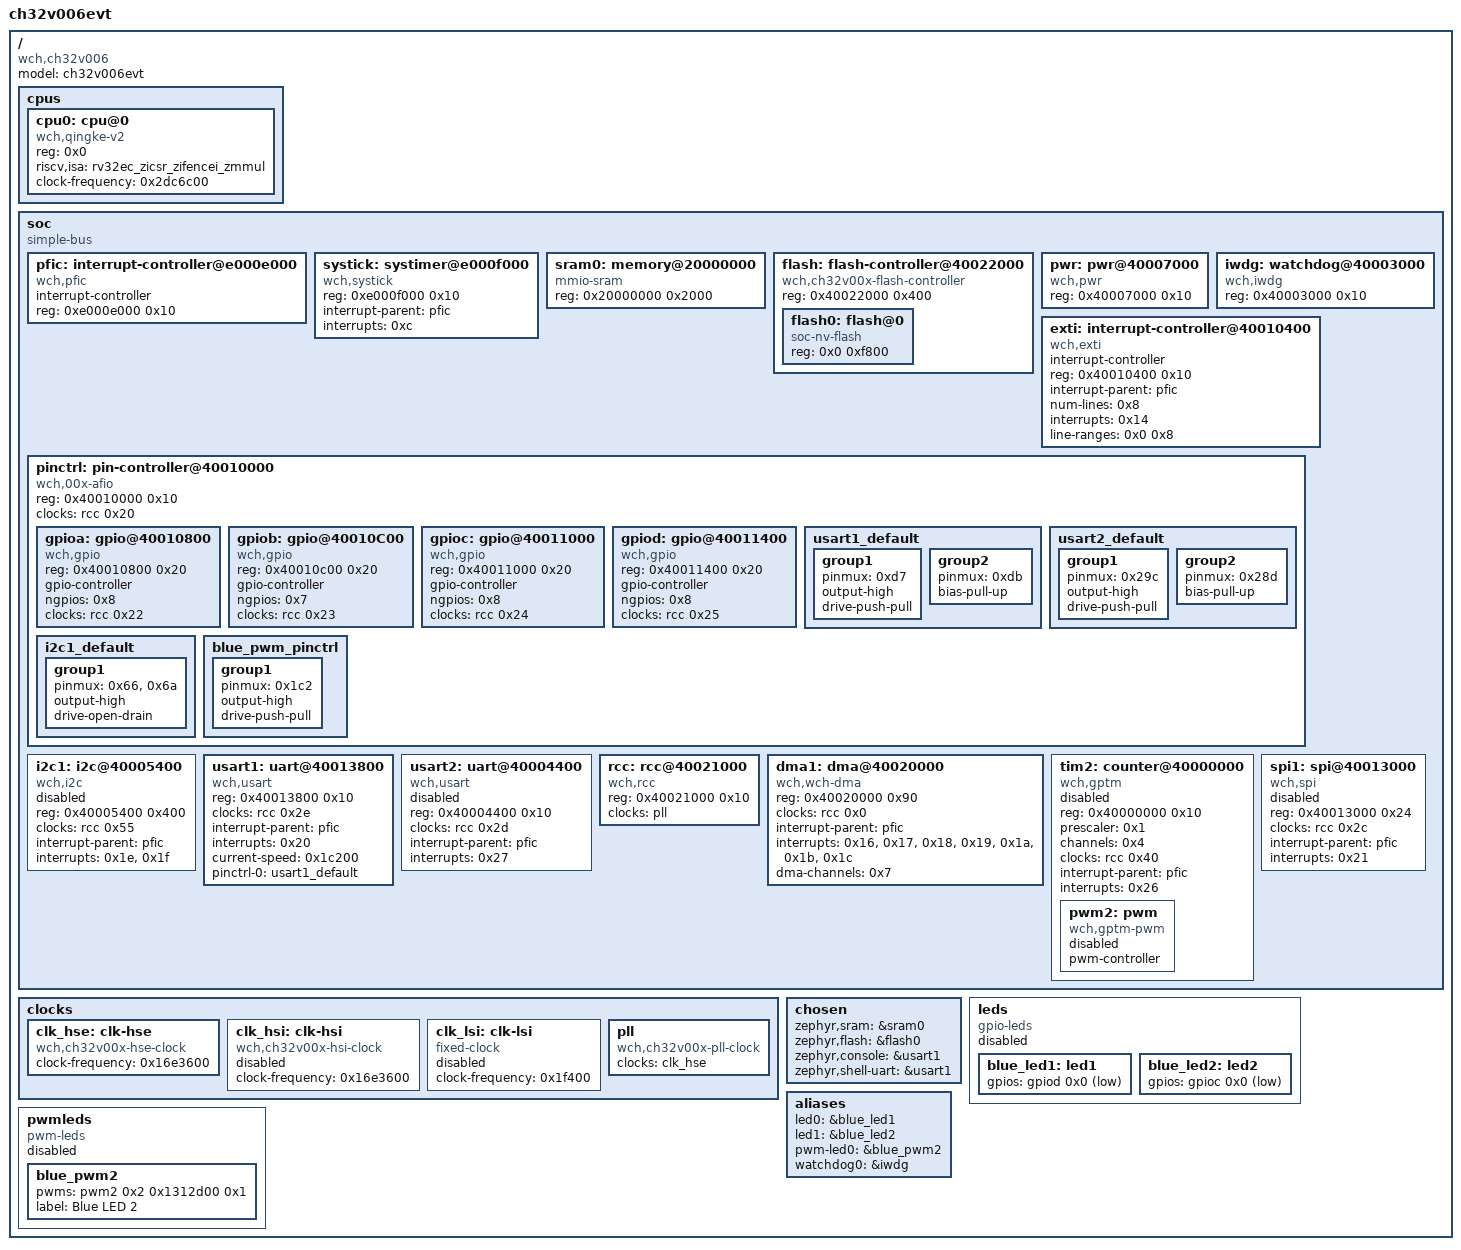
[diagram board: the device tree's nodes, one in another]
/dts-v1/;

/* node '/' defined in zephyr/dts/riscv/wch/qingke-v2c.dtsi:7 */
/ {
	#address-cells = < 0x1 >;    /* in zephyr/dts/riscv/wch/qingke-v2c.dtsi:8 */
	#size-cells = < 0x1 >;       /* in zephyr/dts/riscv/wch/qingke-v2c.dtsi:9 */
	model = "ch32v006evt";       /* in zephyr/boards/wch/ch32v006evt/ch32v006evt.dts:16 */
	compatible = "wch,ch32v006"; /* in zephyr/boards/wch/ch32v006evt/ch32v006evt.dts:17 */

	/* node '/cpus' defined in zephyr/dts/riscv/wch/qingke-v2c.dtsi:11 */
	cpus {
		#address-cells = < 0x1 >; /* in zephyr/dts/riscv/wch/qingke-v2c.dtsi:12 */
		#size-cells = < 0x0 >;    /* in zephyr/dts/riscv/wch/qingke-v2c.dtsi:13 */

		/* node '/cpus/cpu@0' defined in zephyr/dts/riscv/wch/qingke-v2c.dtsi:15 */
		cpu0: cpu@0 {
			device_type = "cpu";                       /* in zephyr/dts/riscv/wch/qingke-v2c.dtsi:16 */
			compatible = "wch,qingke-v2";              /* in zephyr/dts/riscv/wch/qingke-v2c.dtsi:17 */
			reg = < 0x0 >;                             /* in zephyr/dts/riscv/wch/qingke-v2c.dtsi:18 */
			riscv,isa = "rv32ec_zicsr_zifencei_zmmul"; /* in zephyr/dts/riscv/wch/qingke-v2c.dtsi:19 */
			clock-frequency = < 0x2dc6c00 >;           /* in zephyr/dts/riscv/wch/ch32v0/ch32v006.dtsi:212 */
		};
	};

	/* node '/soc' defined in zephyr/dts/riscv/wch/qingke-v2c.dtsi:23 */
	soc {
		#address-cells = < 0x1 >;  /* in zephyr/dts/riscv/wch/qingke-v2c.dtsi:24 */
		#size-cells = < 0x1 >;     /* in zephyr/dts/riscv/wch/qingke-v2c.dtsi:25 */
		compatible = "simple-bus"; /* in zephyr/dts/riscv/wch/qingke-v2c.dtsi:26 */
		ranges;                    /* in zephyr/dts/riscv/wch/qingke-v2c.dtsi:27 */

		/* node '/soc/interrupt-controller@e000e000' defined in zephyr/dts/riscv/wch/qingke-v2c.dtsi:29 */
		pfic: interrupt-controller@e000e000 {
			compatible = "wch,pfic";    /* in zephyr/dts/riscv/wch/qingke-v2c.dtsi:30 */
			#address-cells = < 0x0 >;   /* in zephyr/dts/riscv/wch/qingke-v2c.dtsi:31 */
			#interrupt-cells = < 0x1 >; /* in zephyr/dts/riscv/wch/qingke-v2c.dtsi:32 */
			interrupt-controller;       /* in zephyr/dts/riscv/wch/qingke-v2c.dtsi:33 */
			reg = < 0xe000e000 0x10 >;  /* in zephyr/dts/riscv/wch/qingke-v2c.dtsi:34 */
			status = "okay";            /* in zephyr/dts/riscv/wch/qingke-v2c.dtsi:35 */
			phandle = < 0x1 >;          /* in zephyr/dts/riscv/wch/qingke-v2c.dtsi:42 */
		};

		/* node '/soc/systimer@e000f000' defined in zephyr/dts/riscv/wch/qingke-v2c.dtsi:38 */
		systick: systimer@e000f000 {
			compatible = "wch,systick";   /* in zephyr/dts/riscv/wch/qingke-v2c.dtsi:39 */
			reg = < 0xe000f000 0x10 >;    /* in zephyr/dts/riscv/wch/qingke-v2c.dtsi:40 */
			status = "okay";              /* in zephyr/dts/riscv/wch/qingke-v2c.dtsi:41 */
			interrupt-parent = < &pfic >; /* in zephyr/dts/riscv/wch/qingke-v2c.dtsi:42 */
			interrupts = < 0xc >;         /* in zephyr/dts/riscv/wch/qingke-v2c.dtsi:43 */
		};

		/* node '/soc/memory@20000000' defined in zephyr/dts/riscv/wch/ch32v0/ch32v006.dtsi:46 */
		sram0: memory@20000000 {
			compatible = "mmio-sram";    /* in zephyr/dts/riscv/wch/ch32v0/ch32v006.dtsi:47 */
			reg = < 0x20000000 0x2000 >; /* in zephyr/dts/riscv/wch/ch32v0/ch32v006.dtsi:48 */
		};

		/* node '/soc/flash-controller@40022000' defined in zephyr/dts/riscv/wch/ch32v0/ch32v006.dtsi:51 */
		flash: flash-controller@40022000 {
			compatible = "wch,ch32v00x-flash-controller"; /* in zephyr/dts/riscv/wch/ch32v0/ch32v006.dtsi:52 */
			reg = < 0x40022000 0x400 >;                   /* in zephyr/dts/riscv/wch/ch32v0/ch32v006.dtsi:53 */
			#address-cells = < 0x1 >;                     /* in zephyr/dts/riscv/wch/ch32v0/ch32v006.dtsi:55 */
			#size-cells = < 0x1 >;                        /* in zephyr/dts/riscv/wch/ch32v0/ch32v006.dtsi:56 */

			/* node '/soc/flash-controller@40022000/flash@0' defined in zephyr/dts/riscv/wch/ch32v0/ch32v006.dtsi:58 */
			flash0: flash@0 {
				compatible = "soc-nv-flash"; /* in zephyr/dts/riscv/wch/ch32v0/ch32v006.dtsi:59 */
				reg = < 0x0 0xf800 >;        /* in zephyr/dts/riscv/wch/ch32v0/ch32v006.dtsi:60 */
			};
		};

		/* node '/soc/pwr@40007000' defined in zephyr/dts/riscv/wch/ch32v0/ch32v006.dtsi:64 */
		pwr: pwr@40007000 {
			compatible = "wch,pwr";    /* in zephyr/dts/riscv/wch/ch32v0/ch32v006.dtsi:65 */
			reg = < 0x40007000 0x10 >; /* in zephyr/dts/riscv/wch/ch32v0/ch32v006.dtsi:66 */
		};

		/* node '/soc/watchdog@40003000' defined in zephyr/dts/riscv/wch/ch32v0/ch32v006.dtsi:69 */
		iwdg: watchdog@40003000 {
			compatible = "wch,iwdg";   /* in zephyr/dts/riscv/wch/ch32v0/ch32v006.dtsi:70 */
			reg = < 0x40003000 0x10 >; /* in zephyr/dts/riscv/wch/ch32v0/ch32v006.dtsi:71 */
			status = "okay";           /* in zephyr/boards/wch/ch32v006evt/ch32v006evt.dts:98 */
		};

		/* node '/soc/interrupt-controller@40010400' defined in zephyr/dts/riscv/wch/ch32v0/ch32v006.dtsi:75 */
		exti: interrupt-controller@40010400 {
			compatible = "wch,exti";      /* in zephyr/dts/riscv/wch/ch32v0/ch32v006.dtsi:76 */
			interrupt-controller;         /* in zephyr/dts/riscv/wch/ch32v0/ch32v006.dtsi:77 */
			#interrupt-cells = < 0x1 >;   /* in zephyr/dts/riscv/wch/ch32v0/ch32v006.dtsi:78 */
			reg = < 0x40010400 0x10 >;    /* in zephyr/dts/riscv/wch/ch32v0/ch32v006.dtsi:79 */
			interrupt-parent = < &pfic >; /* in zephyr/dts/riscv/wch/ch32v0/ch32v006.dtsi:80 */
			num-lines = < 0x8 >;          /* in zephyr/dts/riscv/wch/ch32v0/ch32v006.dtsi:81 */
			interrupts = < 0x14 >;        /* in zephyr/dts/riscv/wch/ch32v0/ch32v006.dtsi:82 */
			line-ranges = < 0x0 0x8 >;    /* in zephyr/dts/riscv/wch/ch32v0/ch32v006.dtsi:83 */
			interrupt-names = "line0-7";  /* in zephyr/dts/riscv/wch/ch32v0/ch32v006.dtsi:84 */
			status = "okay";              /* in zephyr/boards/wch/ch32v006evt/ch32v006evt.dts:79 */
		};

		/* node '/soc/pin-controller@40010000' defined in zephyr/dts/riscv/wch/ch32v0/ch32v006.dtsi:88 */
		pinctrl: pin-controller@40010000 {
			compatible = "wch,00x-afio"; /* in zephyr/dts/riscv/wch/ch32v0/ch32v006.dtsi:89 */
			reg = < 0x40010000 0x10 >;   /* in zephyr/dts/riscv/wch/ch32v0/ch32v006.dtsi:90 */
			#address-cells = < 0x1 >;    /* in zephyr/dts/riscv/wch/ch32v0/ch32v006.dtsi:91 */
			#size-cells = < 0x1 >;       /* in zephyr/dts/riscv/wch/ch32v0/ch32v006.dtsi:92 */
			clocks = < &rcc 0x20 >;      /* in zephyr/dts/riscv/wch/ch32v0/ch32v006.dtsi:93 */
			status = "okay";             /* in zephyr/dts/riscv/wch/ch32v0/ch32v006.dtsi:94 */

			/* node '/soc/pin-controller@40010000/gpio@40010800' defined in zephyr/dts/riscv/wch/ch32v0/ch32v006.dtsi:96 */
			gpioa: gpio@40010800 {
				compatible = "wch,gpio";   /* in zephyr/dts/riscv/wch/ch32v0/ch32v006.dtsi:97 */
				reg = < 0x40010800 0x20 >; /* in zephyr/dts/riscv/wch/ch32v0/ch32v006.dtsi:98 */
				gpio-controller;           /* in zephyr/dts/riscv/wch/ch32v0/ch32v006.dtsi:99 */
				#gpio-cells = < 0x2 >;     /* in zephyr/dts/riscv/wch/ch32v0/ch32v006.dtsi:100 */
				ngpios = < 0x8 >;          /* in zephyr/dts/riscv/wch/ch32v0/ch32v006.dtsi:101 */
				clocks = < &rcc 0x22 >;    /* in zephyr/dts/riscv/wch/ch32v0/ch32v006.dtsi:102 */
			};

			/* node '/soc/pin-controller@40010000/gpio@40010C00' defined in zephyr/dts/riscv/wch/ch32v0/ch32v006.dtsi:105 */
			gpiob: gpio@40010C00 {
				compatible = "wch,gpio";   /* in zephyr/dts/riscv/wch/ch32v0/ch32v006.dtsi:106 */
				reg = < 0x40010c00 0x20 >; /* in zephyr/dts/riscv/wch/ch32v0/ch32v006.dtsi:107 */
				gpio-controller;           /* in zephyr/dts/riscv/wch/ch32v0/ch32v006.dtsi:108 */
				#gpio-cells = < 0x2 >;     /* in zephyr/dts/riscv/wch/ch32v0/ch32v006.dtsi:109 */
				ngpios = < 0x7 >;          /* in zephyr/dts/riscv/wch/ch32v0/ch32v006.dtsi:110 */
				clocks = < &rcc 0x23 >;    /* in zephyr/dts/riscv/wch/ch32v0/ch32v006.dtsi:111 */
			};

			/* node '/soc/pin-controller@40010000/gpio@40011000' defined in zephyr/dts/riscv/wch/ch32v0/ch32v006.dtsi:114 */
			gpioc: gpio@40011000 {
				compatible = "wch,gpio";   /* in zephyr/dts/riscv/wch/ch32v0/ch32v006.dtsi:115 */
				reg = < 0x40011000 0x20 >; /* in zephyr/dts/riscv/wch/ch32v0/ch32v006.dtsi:116 */
				gpio-controller;           /* in zephyr/dts/riscv/wch/ch32v0/ch32v006.dtsi:117 */
				#gpio-cells = < 0x2 >;     /* in zephyr/dts/riscv/wch/ch32v0/ch32v006.dtsi:118 */
				ngpios = < 0x8 >;          /* in zephyr/dts/riscv/wch/ch32v0/ch32v006.dtsi:119 */
				clocks = < &rcc 0x24 >;    /* in zephyr/dts/riscv/wch/ch32v0/ch32v006.dtsi:120 */
				status = "okay";           /* in zephyr/boards/wch/ch32v006evt/ch32v006evt.dts:83 */
				phandle = < 0x7 >;         /* in zephyr/boards/wch/ch32v006evt/ch32v006evt.dts:40 */
			};

			/* node '/soc/pin-controller@40010000/gpio@40011400' defined in zephyr/dts/riscv/wch/ch32v0/ch32v006.dtsi:123 */
			gpiod: gpio@40011400 {
				compatible = "wch,gpio";   /* in zephyr/dts/riscv/wch/ch32v0/ch32v006.dtsi:124 */
				reg = < 0x40011400 0x20 >; /* in zephyr/dts/riscv/wch/ch32v0/ch32v006.dtsi:125 */
				gpio-controller;           /* in zephyr/dts/riscv/wch/ch32v0/ch32v006.dtsi:126 */
				#gpio-cells = < 0x2 >;     /* in zephyr/dts/riscv/wch/ch32v0/ch32v006.dtsi:127 */
				ngpios = < 0x8 >;          /* in zephyr/dts/riscv/wch/ch32v0/ch32v006.dtsi:128 */
				clocks = < &rcc 0x25 >;    /* in zephyr/dts/riscv/wch/ch32v0/ch32v006.dtsi:129 */
				status = "okay";           /* in zephyr/boards/wch/ch32v006evt/ch32v006evt.dts:87 */
				phandle = < 0x6 >;         /* in zephyr/boards/wch/ch32v006evt/ch32v006evt.dts:36 */
			};

			/* node '/soc/pin-controller@40010000/usart1_default' defined in zephyr/boards/wch/ch32v006evt/ch32v006evt-pinctrl.dtsi:10 */
			usart1_default: usart1_default {
				phandle = < 0x3 >; /* in zephyr/boards/wch/ch32v006evt/ch32v006evt.dts:93 */

				/* node '/soc/pin-controller@40010000/usart1_default/group1' defined in zephyr/boards/wch/ch32v006evt/ch32v006evt-pinctrl.dtsi:11 */
				group1 {
					pinmux = < 0xd7 >; /* in zephyr/boards/wch/ch32v006evt/ch32v006evt-pinctrl.dtsi:12 */
					output-high;       /* in zephyr/boards/wch/ch32v006evt/ch32v006evt-pinctrl.dtsi:13 */
					drive-push-pull;   /* in zephyr/boards/wch/ch32v006evt/ch32v006evt-pinctrl.dtsi:14 */
				};

				/* node '/soc/pin-controller@40010000/usart1_default/group2' defined in zephyr/boards/wch/ch32v006evt/ch32v006evt-pinctrl.dtsi:17 */
				group2 {
					pinmux = < 0xdb >; /* in zephyr/boards/wch/ch32v006evt/ch32v006evt-pinctrl.dtsi:18 */
					bias-pull-up;      /* in zephyr/boards/wch/ch32v006evt/ch32v006evt-pinctrl.dtsi:19 */
				};
			};

			/* node '/soc/pin-controller@40010000/usart2_default' defined in zephyr/boards/wch/ch32v006evt/ch32v006evt-pinctrl.dtsi:23 */
			usart2_default: usart2_default {

				/* node '/soc/pin-controller@40010000/usart2_default/group1' defined in zephyr/boards/wch/ch32v006evt/ch32v006evt-pinctrl.dtsi:24 */
				group1 {
					pinmux = < 0x29c >; /* in zephyr/boards/wch/ch32v006evt/ch32v006evt-pinctrl.dtsi:25 */
					output-high;        /* in zephyr/boards/wch/ch32v006evt/ch32v006evt-pinctrl.dtsi:26 */
					drive-push-pull;    /* in zephyr/boards/wch/ch32v006evt/ch32v006evt-pinctrl.dtsi:27 */
				};

				/* node '/soc/pin-controller@40010000/usart2_default/group2' defined in zephyr/boards/wch/ch32v006evt/ch32v006evt-pinctrl.dtsi:30 */
				group2 {
					pinmux = < 0x28d >; /* in zephyr/boards/wch/ch32v006evt/ch32v006evt-pinctrl.dtsi:31 */
					bias-pull-up;       /* in zephyr/boards/wch/ch32v006evt/ch32v006evt-pinctrl.dtsi:32 */
				};
			};

			/* node '/soc/pin-controller@40010000/i2c1_default' defined in zephyr/boards/wch/ch32v006evt/ch32v006evt-pinctrl.dtsi:36 */
			i2c1_default: i2c1_default {

				/* node '/soc/pin-controller@40010000/i2c1_default/group1' defined in zephyr/boards/wch/ch32v006evt/ch32v006evt-pinctrl.dtsi:37 */
				group1 {
					pinmux = < 0x66 >,
					         < 0x6a >; /* in zephyr/boards/wch/ch32v006evt/ch32v006evt-pinctrl.dtsi:38 */
					output-high;       /* in zephyr/boards/wch/ch32v006evt/ch32v006evt-pinctrl.dtsi:39 */
					drive-open-drain;  /* in zephyr/boards/wch/ch32v006evt/ch32v006evt-pinctrl.dtsi:40 */
				};
			};

			/* node '/soc/pin-controller@40010000/blue_pwm_pinctrl' defined in zephyr/boards/wch/ch32v006evt/ch32v006evt-pinctrl.dtsi:44 */
			blue_pwm_pinctrl: blue_pwm_pinctrl {

				/* node '/soc/pin-controller@40010000/blue_pwm_pinctrl/group1' defined in zephyr/boards/wch/ch32v006evt/ch32v006evt-pinctrl.dtsi:45 */
				group1 {
					pinmux = < 0x1c2 >; /* in zephyr/boards/wch/ch32v006evt/ch32v006evt-pinctrl.dtsi:46 */
					output-high;        /* in zephyr/boards/wch/ch32v006evt/ch32v006evt-pinctrl.dtsi:47 */
					drive-push-pull;    /* in zephyr/boards/wch/ch32v006evt/ch32v006evt-pinctrl.dtsi:48 */
				};
			};
		};

		/* node '/soc/i2c@40005400' defined in zephyr/dts/riscv/wch/ch32v0/ch32v006.dtsi:133 */
		i2c1: i2c@40005400 {
			compatible = "wch,i2c";       /* in zephyr/dts/riscv/wch/ch32v0/ch32v006.dtsi:134 */
			#address-cells = < 0x1 >;     /* in zephyr/dts/riscv/wch/ch32v0/ch32v006.dtsi:135 */
			#size-cells = < 0x0 >;        /* in zephyr/dts/riscv/wch/ch32v0/ch32v006.dtsi:136 */
			reg = < 0x40005400 0x400 >;   /* in zephyr/dts/riscv/wch/ch32v0/ch32v006.dtsi:137 */
			clocks = < &rcc 0x55 >;       /* in zephyr/dts/riscv/wch/ch32v0/ch32v006.dtsi:138 */
			interrupt-parent = < &pfic >; /* in zephyr/dts/riscv/wch/ch32v0/ch32v006.dtsi:139 */
			interrupts = < 0x1e >,
			             < 0x1f >;        /* in zephyr/dts/riscv/wch/ch32v0/ch32v006.dtsi:140 */
			status = "disabled";          /* in zephyr/dts/riscv/wch/ch32v0/ch32v006.dtsi:141 */
		};

		/* node '/soc/uart@40013800' defined in zephyr/dts/riscv/wch/ch32v0/ch32v006.dtsi:144 */
		usart1: uart@40013800 {
			compatible = "wch,usart";        /* in zephyr/dts/riscv/wch/ch32v0/ch32v006.dtsi:145 */
			reg = < 0x40013800 0x10 >;       /* in zephyr/dts/riscv/wch/ch32v0/ch32v006.dtsi:146 */
			clocks = < &rcc 0x2e >;          /* in zephyr/dts/riscv/wch/ch32v0/ch32v006.dtsi:147 */
			interrupt-parent = < &pfic >;    /* in zephyr/dts/riscv/wch/ch32v0/ch32v006.dtsi:148 */
			interrupts = < 0x20 >;           /* in zephyr/dts/riscv/wch/ch32v0/ch32v006.dtsi:149 */
			status = "okay";                 /* in zephyr/boards/wch/ch32v006evt/ch32v006evt.dts:91 */
			current-speed = < 0x1c200 >;     /* in zephyr/boards/wch/ch32v006evt/ch32v006evt.dts:92 */
			pinctrl-0 = < &usart1_default >; /* in zephyr/boards/wch/ch32v006evt/ch32v006evt.dts:93 */
			pinctrl-names = "default";       /* in zephyr/boards/wch/ch32v006evt/ch32v006evt.dts:94 */
		};

		/* node '/soc/uart@40004400' defined in zephyr/dts/riscv/wch/ch32v0/ch32v006.dtsi:153 */
		usart2: uart@40004400 {
			compatible = "wch,usart";     /* in zephyr/dts/riscv/wch/ch32v0/ch32v006.dtsi:154 */
			reg = < 0x40004400 0x10 >;    /* in zephyr/dts/riscv/wch/ch32v0/ch32v006.dtsi:155 */
			clocks = < &rcc 0x2d >;       /* in zephyr/dts/riscv/wch/ch32v0/ch32v006.dtsi:156 */
			interrupt-parent = < &pfic >; /* in zephyr/dts/riscv/wch/ch32v0/ch32v006.dtsi:157 */
			interrupts = < 0x27 >;        /* in zephyr/dts/riscv/wch/ch32v0/ch32v006.dtsi:158 */
			status = "disabled";          /* in zephyr/dts/riscv/wch/ch32v0/ch32v006.dtsi:159 */
		};

		/* node '/soc/rcc@40021000' defined in zephyr/dts/riscv/wch/ch32v0/ch32v006.dtsi:162 */
		rcc: rcc@40021000 {
			compatible = "wch,rcc";    /* in zephyr/dts/riscv/wch/ch32v0/ch32v006.dtsi:163 */
			reg = < 0x40021000 0x10 >; /* in zephyr/dts/riscv/wch/ch32v0/ch32v006.dtsi:164 */
			#clock-cells = < 0x1 >;    /* in zephyr/dts/riscv/wch/ch32v0/ch32v006.dtsi:165 */
			status = "okay";           /* in zephyr/dts/riscv/wch/ch32v0/ch32v006.dtsi:166 */
			clocks = < &pll >;         /* in zephyr/boards/wch/ch32v006evt/ch32v006evt.dts:75 */
			phandle = < 0x2 >;         /* in zephyr/dts/riscv/wch/ch32v0/ch32v006.dtsi:93 */
		};

		/* node '/soc/dma@40020000' defined in zephyr/dts/riscv/wch/ch32v0/ch32v006.dtsi:169 */
		dma1: dma@40020000 {
			compatible = "wch,wch-dma";   /* in zephyr/dts/riscv/wch/ch32v0/ch32v006.dtsi:170 */
			reg = < 0x40020000 0x90 >;    /* in zephyr/dts/riscv/wch/ch32v0/ch32v006.dtsi:171 */
			clocks = < &rcc 0x0 >;        /* in zephyr/dts/riscv/wch/ch32v0/ch32v006.dtsi:172 */
			#dma-cells = < 0x1 >;         /* in zephyr/dts/riscv/wch/ch32v0/ch32v006.dtsi:173 */
			interrupt-parent = < &pfic >; /* in zephyr/dts/riscv/wch/ch32v0/ch32v006.dtsi:174 */
			interrupts = < 0x16 >,
			             < 0x17 >,
			             < 0x18 >,
			             < 0x19 >,
			             < 0x1a >,
			             < 0x1b >,
			             < 0x1c >;        /* in zephyr/dts/riscv/wch/ch32v0/ch32v006.dtsi:175 */
			dma-channels = < 0x7 >;       /* in zephyr/dts/riscv/wch/ch32v0/ch32v006.dtsi:176 */
		};

		/* node '/soc/counter@40000000' defined in zephyr/dts/riscv/wch/ch32v0/ch32v006.dtsi:179 */
		tim2: counter@40000000 {
			compatible = "wch,gptm";      /* in zephyr/dts/riscv/wch/ch32v0/ch32v006.dtsi:180 */
			reg = < 0x40000000 0x10 >;    /* in zephyr/dts/riscv/wch/ch32v0/ch32v006.dtsi:181 */
			prescaler = < 0x1 >;          /* in zephyr/dts/riscv/wch/ch32v0/ch32v006.dtsi:182 */
			channels = < 0x4 >;           /* in zephyr/dts/riscv/wch/ch32v0/ch32v006.dtsi:183 */
			clocks = < &rcc 0x40 >;       /* in zephyr/dts/riscv/wch/ch32v0/ch32v006.dtsi:184 */
			interrupt-parent = < &pfic >; /* in zephyr/dts/riscv/wch/ch32v0/ch32v006.dtsi:185 */
			interrupts = < 0x26 >;        /* in zephyr/dts/riscv/wch/ch32v0/ch32v006.dtsi:186 */
			interrupt-names = "global";   /* in zephyr/dts/riscv/wch/ch32v0/ch32v006.dtsi:187 */
			status = "disabled";          /* in zephyr/dts/riscv/wch/ch32v0/ch32v006.dtsi:188 */

			/* node '/soc/counter@40000000/pwm' defined in zephyr/dts/riscv/wch/ch32v0/ch32v006.dtsi:190 */
			pwm2: pwm {
				compatible = "wch,gptm-pwm"; /* in zephyr/dts/riscv/wch/ch32v0/ch32v006.dtsi:191 */
				pwm-controller;              /* in zephyr/dts/riscv/wch/ch32v0/ch32v006.dtsi:192 */
				#pwm-cells = < 0x3 >;        /* in zephyr/dts/riscv/wch/ch32v0/ch32v006.dtsi:193 */
				status = "disabled";         /* in zephyr/dts/riscv/wch/ch32v0/ch32v006.dtsi:194 */
				phandle = < 0x8 >;           /* in zephyr/boards/wch/ch32v006evt/ch32v006evt.dts:51 */
			};
		};

		/* node '/soc/spi@40013000' defined in zephyr/dts/riscv/wch/ch32v0/ch32v006.dtsi:198 */
		spi1: spi@40013000 {
			compatible = "wch,spi";       /* in zephyr/dts/riscv/wch/ch32v0/ch32v006.dtsi:199 */
			reg = < 0x40013000 0x24 >;    /* in zephyr/dts/riscv/wch/ch32v0/ch32v006.dtsi:200 */
			clocks = < &rcc 0x2c >;       /* in zephyr/dts/riscv/wch/ch32v0/ch32v006.dtsi:201 */
			interrupt-parent = < &pfic >; /* in zephyr/dts/riscv/wch/ch32v0/ch32v006.dtsi:202 */
			interrupts = < 0x21 >;        /* in zephyr/dts/riscv/wch/ch32v0/ch32v006.dtsi:203 */
			status = "disabled";          /* in zephyr/dts/riscv/wch/ch32v0/ch32v006.dtsi:204 */
			#address-cells = < 0x1 >;     /* in zephyr/dts/riscv/wch/ch32v0/ch32v006.dtsi:205 */
			#size-cells = < 0x0 >;        /* in zephyr/dts/riscv/wch/ch32v0/ch32v006.dtsi:206 */
		};
	};

	/* node '/clocks' defined in zephyr/dts/riscv/wch/ch32v0/ch32v006.dtsi:17 */
	clocks {

		/* node '/clocks/clk-hse' defined in zephyr/dts/riscv/wch/ch32v0/ch32v006.dtsi:18 */
		clk_hse: clk-hse {
			#clock-cells = < 0x0 >;                /* in zephyr/dts/riscv/wch/ch32v0/ch32v006.dtsi:19 */
			compatible = "wch,ch32v00x-hse-clock"; /* in zephyr/dts/riscv/wch/ch32v0/ch32v006.dtsi:20 */
			clock-frequency = < 0x16e3600 >;       /* in zephyr/boards/wch/ch32v006evt/ch32v006evt.dts:65 */
			status = "okay";                       /* in zephyr/boards/wch/ch32v006evt/ch32v006evt.dts:66 */
			phandle = < 0x5 >;                     /* in zephyr/boards/wch/ch32v006evt/ch32v006evt.dts:70 */
		};

		/* node '/clocks/clk-hsi' defined in zephyr/dts/riscv/wch/ch32v0/ch32v006.dtsi:24 */
		clk_hsi: clk-hsi {
			#clock-cells = < 0x0 >;                /* in zephyr/dts/riscv/wch/ch32v0/ch32v006.dtsi:25 */
			compatible = "wch,ch32v00x-hsi-clock"; /* in zephyr/dts/riscv/wch/ch32v0/ch32v006.dtsi:26 */
			clock-frequency = < 0x16e3600 >;       /* in zephyr/dts/riscv/wch/ch32v0/ch32v006.dtsi:27 */
			status = "disabled";                   /* in zephyr/dts/riscv/wch/ch32v0/ch32v006.dtsi:28 */
		};

		/* node '/clocks/clk-lsi' defined in zephyr/dts/riscv/wch/ch32v0/ch32v006.dtsi:31 */
		clk_lsi: clk-lsi {
			#clock-cells = < 0x0 >;        /* in zephyr/dts/riscv/wch/ch32v0/ch32v006.dtsi:32 */
			compatible = "fixed-clock";    /* in zephyr/dts/riscv/wch/ch32v0/ch32v006.dtsi:33 */
			clock-frequency = < 0x1f400 >; /* in zephyr/dts/riscv/wch/ch32v0/ch32v006.dtsi:34 */
			status = "disabled";           /* in zephyr/dts/riscv/wch/ch32v0/ch32v006.dtsi:35 */
		};

		/* node '/clocks/pll' defined in zephyr/dts/riscv/wch/ch32v0/ch32v006.dtsi:38 */
		pll: pll {
			#clock-cells = < 0x0 >;                /* in zephyr/dts/riscv/wch/ch32v0/ch32v006.dtsi:39 */
			compatible = "wch,ch32v00x-pll-clock"; /* in zephyr/dts/riscv/wch/ch32v0/ch32v006.dtsi:40 */
			clocks = < &clk_hse >;                 /* in zephyr/boards/wch/ch32v006evt/ch32v006evt.dts:70 */
			status = "okay";                       /* in zephyr/boards/wch/ch32v006evt/ch32v006evt.dts:71 */
			phandle = < 0x4 >;                     /* in zephyr/boards/wch/ch32v006evt/ch32v006evt.dts:75 */
		};
	};

	/* node '/chosen' defined in zephyr/boards/wch/ch32v006evt/ch32v006evt.dts:19 */
	chosen {
		zephyr,sram = &sram0;        /* in zephyr/boards/wch/ch32v006evt/ch32v006evt.dts:20 */
		zephyr,flash = &flash0;      /* in zephyr/boards/wch/ch32v006evt/ch32v006evt.dts:21 */
		zephyr,console = &usart1;    /* in zephyr/boards/wch/ch32v006evt/ch32v006evt.dts:22 */
		zephyr,shell-uart = &usart1; /* in zephyr/boards/wch/ch32v006evt/ch32v006evt.dts:23 */
	};

	/* node '/leds' defined in zephyr/boards/wch/ch32v006evt/ch32v006evt.dts:26 */
	leds {
		compatible = "gpio-leds"; /* in zephyr/boards/wch/ch32v006evt/ch32v006evt.dts:27 */
		status = "disabled";      /* in zephyr/boards/wch/ch32v006evt/ch32v006evt.dts:33 */

		/* node '/leds/led1' defined in zephyr/boards/wch/ch32v006evt/ch32v006evt.dts:35 */
		blue_led1: led1 {
			gpios = < &gpiod 0x0 0x1 >; /* in zephyr/boards/wch/ch32v006evt/ch32v006evt.dts:36 */
		};

		/* node '/leds/led2' defined in zephyr/boards/wch/ch32v006evt/ch32v006evt.dts:39 */
		blue_led2: led2 {
			gpios = < &gpioc 0x0 0x1 >; /* in zephyr/boards/wch/ch32v006evt/ch32v006evt.dts:40 */
		};
	};

	/* node '/pwmleds' defined in zephyr/boards/wch/ch32v006evt/ch32v006evt.dts:44 */
	pwmleds: pwmleds {
		compatible = "pwm-leds"; /* in zephyr/boards/wch/ch32v006evt/ch32v006evt.dts:45 */
		status = "disabled";     /* in zephyr/boards/wch/ch32v006evt/ch32v006evt.dts:46 */

		/* node '/pwmleds/blue_pwm2' defined in zephyr/boards/wch/ch32v006evt/ch32v006evt.dts:50 */
		blue_pwm2: blue_pwm2 {
			pwms = < &pwm2 0x2 0x1312d00 0x1 >; /* in zephyr/boards/wch/ch32v006evt/ch32v006evt.dts:51 */
			label = "Blue LED 2";               /* in zephyr/boards/wch/ch32v006evt/ch32v006evt.dts:52 */
		};
	};

	/* node '/aliases' defined in zephyr/boards/wch/ch32v006evt/ch32v006evt.dts:56 */
	aliases {
		led0 = &blue_led1;     /* in zephyr/boards/wch/ch32v006evt/ch32v006evt.dts:57 */
		led1 = &blue_led2;     /* in zephyr/boards/wch/ch32v006evt/ch32v006evt.dts:58 */
		pwm-led0 = &blue_pwm2; /* in zephyr/boards/wch/ch32v006evt/ch32v006evt.dts:59 */
		watchdog0 = &iwdg;     /* in zephyr/boards/wch/ch32v006evt/ch32v006evt.dts:60 */
	};
};
